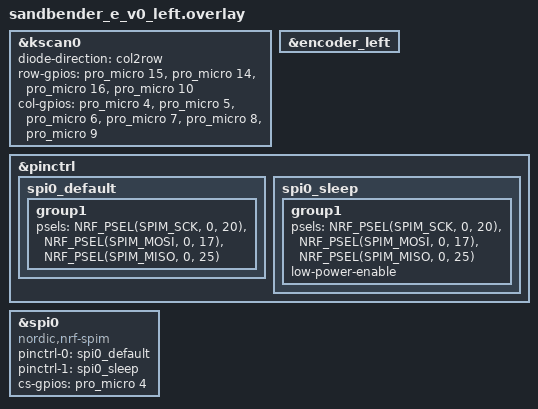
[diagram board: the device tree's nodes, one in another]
#include "sandbender_e_v0.dtsi"
// https://github.com/zmkfirmware/zmk/blob/main/app/boards/arm/nice_nano/arduino_pro_micro_pins.dtsi
&kscan0 {
    diode-direction = "col2row";

    // top to bottom actually -- called col in schematic for some reason
    row-gpios
        = <&pro_micro 15 (GPIO_ACTIVE_HIGH)>  // COL 1 (TOP)
        , <&pro_micro 14 (GPIO_ACTIVE_HIGH)>  // COL 2 (MID)
        , <&pro_micro 16 (GPIO_ACTIVE_HIGH)>  // COL 3 (LOWER)
        , <&pro_micro 10 (GPIO_ACTIVE_HIGH)>  // COL 4 (THUMB + ROT)
    ;

    // left to right -- called row in schematic for some reason
    col-gpios
        = <&pro_micro 4 (GPIO_ACTIVE_HIGH | GPIO_PULL_DOWN)>  // ROW 0 (outer)
        , <&pro_micro 5 (GPIO_ACTIVE_HIGH | GPIO_PULL_DOWN)>  // ROW 1 (pinky)
        , <&pro_micro 6 (GPIO_ACTIVE_HIGH | GPIO_PULL_DOWN)>  // ROW 2 (ring)
        , <&pro_micro 7 (GPIO_ACTIVE_HIGH | GPIO_PULL_DOWN)>  // ROW 3 (middle + TTUCK)
        , <&pro_micro 8 (GPIO_ACTIVE_HIGH | GPIO_PULL_DOWN)>  // ROW 4 (index + TREST)
        , <&pro_micro 9 (GPIO_ACTIVE_HIGH | GPIO_PULL_DOWN)>  // ROW 5 (inner + ROT)
        ;
};

&encoder_left {
    status = "okay";
};

&pinctrl {
    spi0_default: spi0_default {
        group1 {
            psels = <NRF_PSEL(SPIM_SCK, 0, 20)>,
                <NRF_PSEL(SPIM_MOSI, 0, 17)>,
                <NRF_PSEL(SPIM_MISO, 0, 25)>;
        };
    };
    spi0_sleep: spi0_sleep {
        group1 {
            psels = <NRF_PSEL(SPIM_SCK, 0, 20)>,
                <NRF_PSEL(SPIM_MOSI, 0, 17)>,
                <NRF_PSEL(SPIM_MISO, 0, 25)>;
            low-power-enable;
        };
    };
};

nice_view_spi: &spi0 {
    compatible = "nordic,nrf-spim";
    pinctrl-0 = <&spi0_default>;
    pinctrl-1 = <&spi0_sleep>;
    pinctrl-names = "default", "sleep";
    cs-gpios = <&pro_micro 4 GPIO_ACTIVE_HIGH>;
};
